# STM32G483xx register map
File version: 1.0
Registers are 32-bit, read-write, reset 0x0 unless marked. A register's access mark holds for its fields unless they carry their own. Offsets are from the block's base; [hi:lo] are bit positions; {n}, {i} and the like mark numbered series.

## FLASH — FLASH Registers
Base 0x40022000
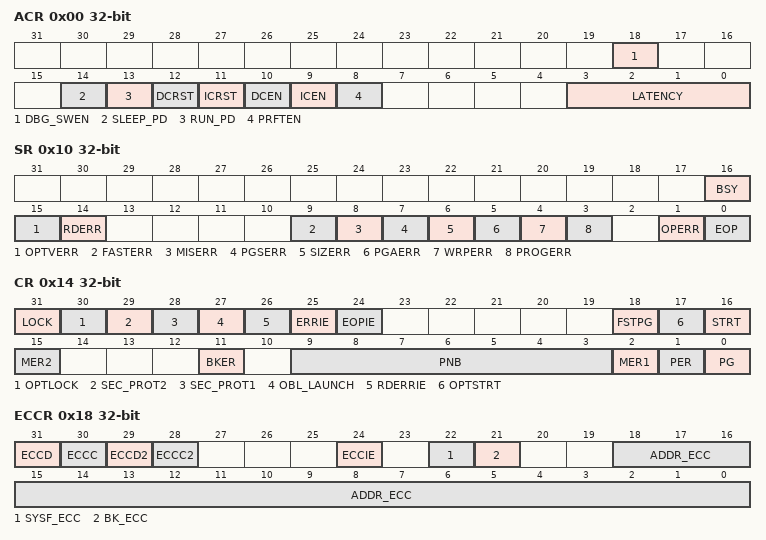
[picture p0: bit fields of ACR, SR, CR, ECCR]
0x00 ACR — FLASH access control register
  [18] DBG_SWEN — Software disable for debugger
  [14] SLEEP_PD — Flash power down mode during sleep
  [13] RUN_PD — Flash power down mode during run
  [12] DCRST
  [11] ICRST
  [10] DCEN
  [9] ICEN
  [8] PRFTEN
  [3:0] LATENCY
    0=FLASH Zero wait state; 1=FLASH One wait state; 2=FLASH Two wait states; 3=FLASH Three wait states; 4=FLASH Four wait states; 5=FLASH five wait state; 6=FLASH six wait state; 7=FLASH seven wait states; 8=FLASH eight wait states; 9=FLASH nine wait states; 10=FLASH ten wait states; 11=FLASH eleven wait states; 12=FLASH twelve wait states; 13=FLASH thirteen wait states; 14=FLASH fourteen wait states; 15=FLASH fifteen wait states
0x04 PDKEYR — FLASH power down key register
0x08 KEYR — FLASH key register
0x0C OPTKEYR — FLASH option key register
0x10 SR — FLASH status register
  [16] BSY, [15] OPTVERR, [14] RDERR, [9] FASTERR, [8] MISERR, [7] PGSERR, [6] SIZERR, [5] PGAERR, [4] WRPERR, [3] PROGERR, [1] OPERR, [0] EOP
0x14 CR — FLASH control register
  [31] LOCK, [30] OPTLOCK, [29] SEC_PROT2, [28] SEC_PROT1, [27] OBL_LAUNCH, [26] RDERRIE, [25] ERRIE, [24] EOPIE, [18] FSTPG, [17] OPTSTRT, [16] STRT, [15] MER2, [11] BKER, [9:3] PNB, [2] MER1, [1] PER, [0] PG
0x18 ECCR — FLASH ECC register
  [31] ECCD, [30] ECCC, [29] ECCD2, [28] ECCC2, [24] ECCIE, [22] SYSF_ECC, [21] BK_ECC, [18:0] ADDR_ECC
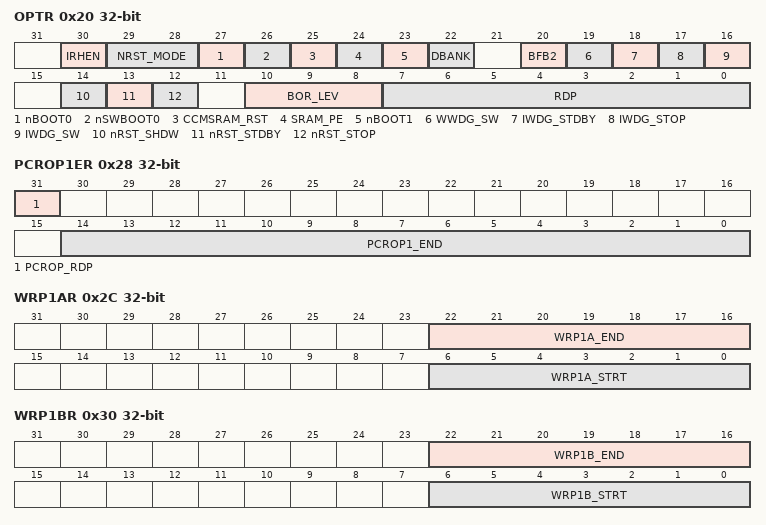
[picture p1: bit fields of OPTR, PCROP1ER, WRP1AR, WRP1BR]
0x20 OPTR — FLASH option register
  [30] IRHEN, [29:28] NRST_MODE, [27] nBOOT0, [26] nSWBOOT0, [25] CCMSRAM_RST, [24] SRAM_PE, [23] nBOOT1, [22] DBANK, [20] BFB2, [19] WWDG_SW, [18] IWDG_STDBY, [17] IWDG_STOP, [16] IWDG_SW, [14] nRST_SHDW, [13] nRST_STDBY, [12] nRST_STOP, [10:8] BOR_LEV, [7:0] RDP
0x24 PCROP1SR — FLASH bank1 PCROP start address register
  [14:0] PCROP1_STRT
0x28 PCROP1ER — FLASH bank1 PCROP end address register
  [31] PCROP_RDP, [14:0] PCROP1_END
0x2C WRP1AR — FLASH bank1 WRP area A address register
  [22:16] WRP1A_END, [6:0] WRP1A_STRT
0x30 WRP1BR — FLASH bank1 WRP area B address register
  [22:16] WRP1B_END, [6:0] WRP1B_STRT
0x44 PCROP2SR — FLASH bank2 PCROP start address register
  [14:0] PCROP2_STRT
0x48 PCROP2ER — FLASH bank2 PCROP end address register
  [14:0] PCROP2_END
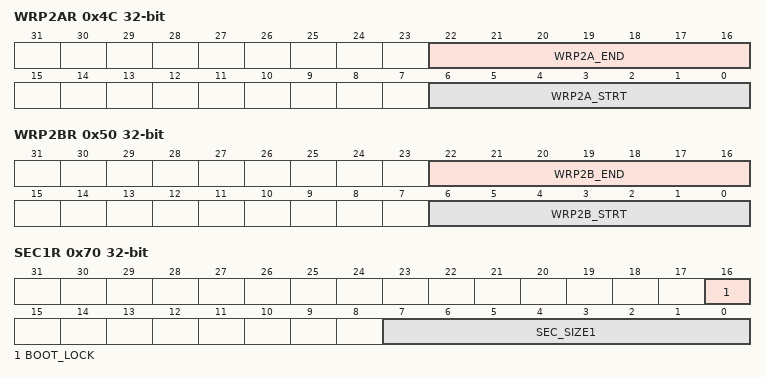
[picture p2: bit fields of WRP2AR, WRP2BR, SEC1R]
0x4C WRP2AR — FLASH bank2 WRP area A address register
  [22:16] WRP2A_END, [6:0] WRP2A_STRT
0x50 WRP2BR — FLASH bank2 WRP area B address register
  [22:16] WRP2B_END, [6:0] WRP2B_STRT
0x70 SEC1R — FLASH Securable memory register bank1
  [16] BOOT_LOCK, [7:0] SEC_SIZE1
0x74 SEC2R — FLASH Securable memory register bank2
  [7:0] SEC_SIZE2

## CRC — CRC calculation unit
Base 0x40023000
0x00 DR — CRC Data register
  [31:0] DR — Data register bits
0x04 IDR — CRC Independent data register
  [31:0] IDR — General-purpose 32-bit data register bits
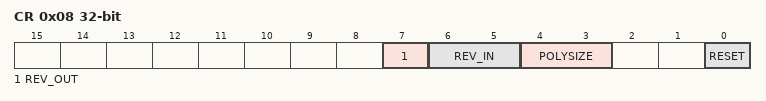
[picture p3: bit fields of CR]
0x08 CR — CRC Control register
  [7] REV_OUT — REV_OUT Reverse Output Data bits
    0=NONE (Output Data bit order not affected); 1=BIT (Output Data bit reversal done by bit)
  [6:5] REV_IN — REV_IN Reverse Input Data bits
    0=NONE (Input Data bit order not affected); 1=BYTE (Input Data bit reversal done by byte); 2=HALFWORD (Input Data bit reversal done by half-word); 3=WORD (Input Data bit reversal done by word)
  [4:3] POLYSIZE — Polynomial size bits
    0=POLYLENGTH_32B (32 bits Polynomial size); 1=POLYLENGTH_16B (16 bits Polynomial size); 2=POLYLENGTH_8B (8 bits Polynomial size); 3=POLYLENGTH_7B (7 bits Polynomial size)
  [0] RESET — RESET the CRC computation unit bit
0x10 INIT — Initial CRC value register
  [31:0] INIT — Initial CRC value bits
0x14 POL — CRC polynomial register
  [31:0] POL — Coefficients of the polynomial

## GPIOA — General Purpose I/O
Base 0x48000000
Same registers: GPIOB 0x48000400, GPIOC 0x48000800, GPIOD 0x48000C00, GPIOE 0x48001000, GPIOF 0x48001400, GPIOG 0x48001800
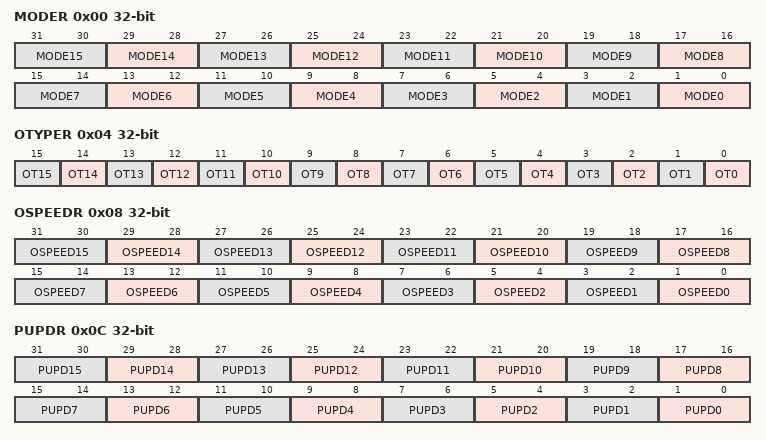
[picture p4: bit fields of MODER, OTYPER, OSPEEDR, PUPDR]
0x00 MODER — GPIO port mode register
  [2n+1:2n] MODE{n} (n=0..15)
0x04 OTYPER — GPIO port output type register
  [n] OT{n} (n=0..15)
0x08 OSPEEDR — GPIO port output speed register
  [2n+1:2n] OSPEED{n} (n=0..15)
0x0C PUPDR — GPIO port pull-up/pull-down register
  [2n+1:2n] PUPD{n} (n=0..15)
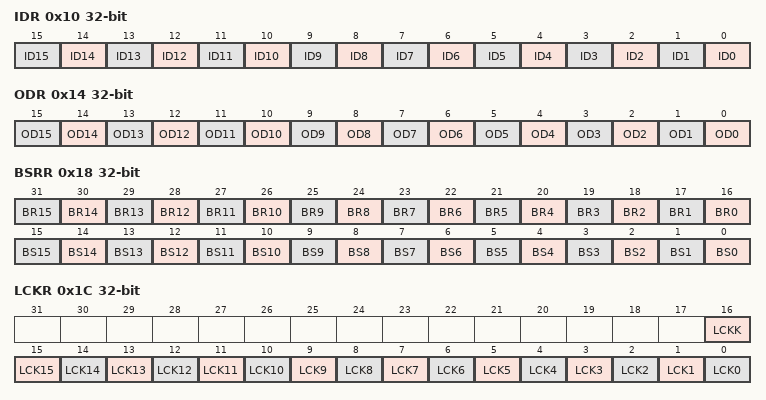
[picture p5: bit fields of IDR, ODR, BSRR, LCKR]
0x10 IDR — GPIO port input data register
  [n] ID{n} (n=0..15)
0x14 ODR — GPIO port output data register
  [n] OD{n} (n=0..15)
0x18 BSRR — GPIO port bit set/reset register
  [n+16] BR{n} (n=0..15), [n] BS{n} (n=0..15)
0x1C LCKR — GPIO port configuration lock register
  [16] LCKK, [n] LCK{n} (n=0..15)
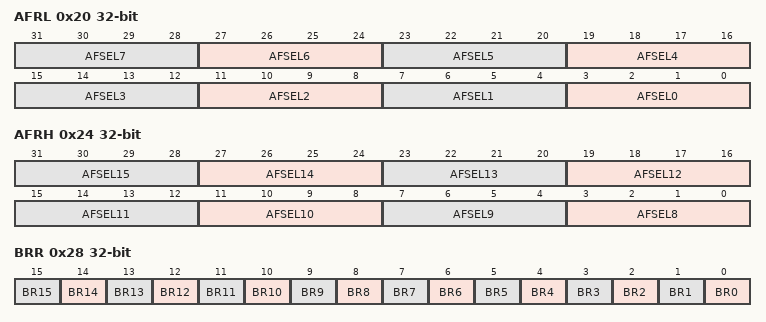
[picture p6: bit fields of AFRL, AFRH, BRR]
0x20 AFRL — GPIO alternate function registers
  [4n+3:4n] AFSEL{n} (n=0..7)
0x24 AFRH — GPIO alternate function registers
  [4n-29:4n-32] AFSEL{n} (n=8..15)
0x28 BRR — GPIO Bit Reset register
  [n] BR{n} (n=0..15)
